VERSION ""

NS_ :

BS_:

BU_: CGW VUM
VAL_TABLE_ TestECUState 1 "ON" 0 "OFF" ;
VAL_TABLE_ vtbSensorReqCause 15 "SNA" 2 "by Request 2" 1 "by Request 1" 0 "normal cycle" ;
VAL_TABLE_ vtbErrorDescription 255 "ERROR" ;

BO_ 515 OBD_Neg_Respond_OBD: 2 CGW
 SG_ sig_sid : 8|8@1- (1,0) [0|0] ""  VUM
 SG_ sig_neg_respond : 0|8@1- (1,0) [0|0] ""  VUM

BO_ 514 OBD_Pos_Respond_OBD: 1 CGW
 SG_ sig_sid : 0|8@1- (1,0) [0|0] ""  VUM

BO_ 1286 ECU_Neg_Respond_OTA: 2 CGW
 SG_ sig_sid : 8|8@1- (1,0) [0|0] ""  VUM
 SG_ sig_neg_respond : 0|8@1- (1,0) [0|0] ""  VUM

BO_ 1285 ECU_Pos_Respond_OTA: 8 CGW
 SG_ sig_data : 16|56@1- (1,0) [0|0] ""  VUM
 SG_ sig_sid : 0|8@1- (1,0) [0|0] ""  VUM

BO_ 1679 VUM_File_Cluster: 8 VUM
 SG_ sig_payload : 0|64@1- (1,0) [0|0] ""  CGW

BO_ 1678 VUM_File_OBD: 8 VUM
 SG_ sig_payload : 0|64@1- (1,0) [0|0] ""  CGW

BO_ 1677 VUM_File_Seat: 8 VUM
 SG_ sig_payload : 0|64@1- (1,0) [0|0] ""  CGW

BO_ 1676 VUM_File_Light: 8 VUM
 SG_ sig_payload : 0|64@1- (1,0) [0|0] ""  CGW

BO_ 1675 VUM_File_Rain: 8 VUM
 SG_ sig_payload : 0|64@1- (1,0) [0|0] ""  CGW

BO_ 1674 VUM_File_Telematic: 8 VUM
 SG_ sig_payload : 0|64@1- (1,0) [0|0] ""  CGW

BO_ 1673 VUM_File_Illuminate: 8 VUM
 SG_ sig_payload : 0|64@1- (1,0) [0|0] ""  CGW

BO_ 1672 VUM_File_ADAS: 8 VUM
 SG_ sig_payload : 0|64@1- (1,0) [0|0] ""  CGW

BO_ 1671 VUM_File_Steering: 8 VUM
 SG_ sig_payload : 0|64@1- (1,0) [0|0] ""  CGW

BO_ 1670 VUM_File_Brake: 8 VUM
 SG_ sig_payload : 0|64@1- (1,0) [0|0] ""  CGW

BO_ 1669 VUM_File_ABS: 8 VUM
 SG_ sig_payload : 0|64@1- (1,0) [0|0] ""  CGW

BO_ 1668 VUM_File_BMS: 8 VUM
 SG_ sig_payload : 0|64@1- (1,0) [0|0] ""  CGW

BO_ 1667 VUM_File_Transmission: 8 VUM
 SG_ sig_payload : 0|64@1- (1,0) [0|0] ""  CGW

BO_ 1666 VUM_File_Motor: 8 VUM
 SG_ sig_payload : 0|64@1- (1,0) [0|0] ""  CGW

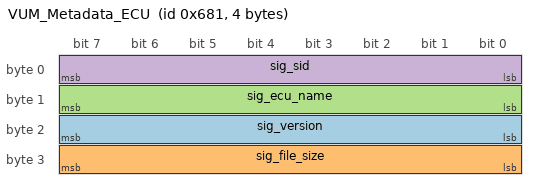
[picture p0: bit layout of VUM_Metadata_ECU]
BO_ 1665 VUM_Metadata_ECU: 4 VUM
 SG_ sig_version : 16|8@1+ (1,0) [0|255] ""  CGW
 SG_ sig_file_size : 24|8@1+ (1,0) [0|255] ""  CGW
 SG_ sig_ecu_name : 8|8@1+ (1,0) [0|255] ""  CGW
 SG_ sig_sid : 0|8@1+ (1,0) [0|255] ""  CGW

BO_ 1664 VUM_Request_ECU: 1 VUM
 SG_ sig_data : 0|56@1- (1,0) [0|0] ""  CGW

BA_DEF_  "DatabaseVersion" STRING ;
BA_DEF_  "Manufacturer" STRING ;
BA_DEF_ BU_  "NodeLayerModules" STRING ;
BA_DEF_  "BusType" STRING ;
BA_DEF_ SG_  "GenSigSendType" ENUM  "Cyclic","OnWrite","OnWriteWithRepetition","OnChange","OnChangeWithRepetition","IfActive","IfActiveWithRepetition","NoSigSendType","NotUsed","NotUsed","NotUsed","NotUsed","NotUsed";
BA_DEF_ BO_  "GenMsgSendType" ENUM  "Cyclic","NotUsed","NotUsed","NotUsed","NotUsed","Cyclic","NotUsed","IfActive","NoMsgSendType","NotUsed","vector_leerstring";
BA_DEF_ BO_  "GenMsgCycleTime" INT 0 50000;
BA_DEF_ BO_  "GenMsgCycleTimeFast" INT 0 50000;
BA_DEF_ BO_  "GenMsgILSupport" ENUM  "No","Yes";
BA_DEF_DEF_  "DatabaseVersion" "";
BA_DEF_DEF_  "Manufacturer" "Vector";
BA_DEF_DEF_  "NodeLayerModules" "CANoeILNLVector.dll";
BA_DEF_DEF_  "BusType" "CAN";
BA_DEF_DEF_  "GenSigSendType" "Cyclic";
BA_DEF_DEF_  "GenMsgSendType" "NoMsgSendType";
BA_DEF_DEF_  "GenMsgCycleTime" 200;
BA_DEF_DEF_  "GenMsgCycleTimeFast" 20;
BA_DEF_DEF_  "GenMsgILSupport" "Yes";
BA_ "DatabaseVersion" "1.1";
BA_ "GenMsgCycleTime" BO_ 515 0;
BA_ "GenMsgCycleTime" BO_ 514 0;
BA_ "GenMsgCycleTime" BO_ 1286 0;
BA_ "GenMsgCycleTime" BO_ 1285 0;
BA_ "GenMsgCycleTime" BO_ 1679 0;
BA_ "GenMsgCycleTime" BO_ 1678 0;
BA_ "GenMsgCycleTime" BO_ 1677 0;
BA_ "GenMsgCycleTime" BO_ 1676 0;
BA_ "GenMsgCycleTime" BO_ 1675 0;
BA_ "GenMsgCycleTime" BO_ 1674 0;
BA_ "GenMsgCycleTime" BO_ 1673 0;
BA_ "GenMsgCycleTime" BO_ 1672 0;
BA_ "GenMsgCycleTime" BO_ 1671 0;
BA_ "GenMsgCycleTime" BO_ 1670 0;
BA_ "GenMsgCycleTime" BO_ 1669 0;
BA_ "GenMsgCycleTime" BO_ 1668 0;
BA_ "GenMsgCycleTime" BO_ 1667 0;
BA_ "GenMsgCycleTime" BO_ 1666 0;
BA_ "GenMsgCycleTime" BO_ 1665 0;
BA_ "GenMsgCycleTime" BO_ 1664 0;
